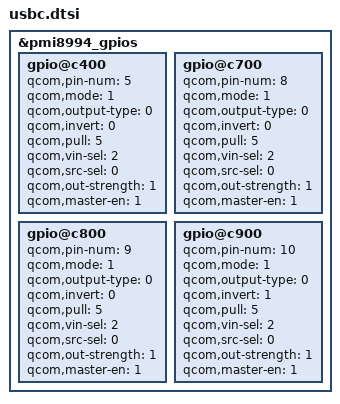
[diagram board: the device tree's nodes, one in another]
/*
 * Lumia 950 RM-1104 4VM_08r USB-C.
 *
 * Lattice iCE5LP2K (UC120 Type-C PHY, firmware bitstream) + TI HD3SS460
 * SuperSpeed mux. No USB Power Delivery. No HVDCP.
 *
 * HD3SS460 POL/AMSEL/EN sit next to GPIO_8/9/10 on sheet 4. Those cannot
 * be TLMM 8/9/10: MSM GPIO 10 is DISPLAY_TE. Hold the mux on PMI8994
 * GPIO 8/9/10 + GPIO 5 VBUS (already OTG switch). No PD PHY node.
 */

&pmi8994_gpios {
	gpio@c400 {	/* GPIO 5  USB_VBUS / OTG SWITCH */
		status = "okay";
		qcom,pin-num = <5>;
		qcom,mode = <1>;		/* digital output */
		qcom,output-type = <0>;		/* CMOS */
		qcom,invert = <0>;		/* VBUS off */
		qcom,pull = <5>;		/* no pull */
		qcom,vin-sel = <2>;		/* 1.8 V */
		qcom,src-sel = <0>;		/* constant */
		qcom,out-strength = <1>;	/* low */
		qcom,master-en = <1>;
	};

	gpio@c700 {	/* GPIO 8  HD3SS460 POL */
		status = "okay";
		qcom,pin-num = <8>;
		qcom,mode = <1>;
		qcom,output-type = <0>;
		qcom,invert = <0>;		/* POL 0 */
		qcom,pull = <5>;
		qcom,vin-sel = <2>;
		qcom,src-sel = <0>;
		qcom,out-strength = <1>;
		qcom,master-en = <1>;
	};

	gpio@c800 {	/* GPIO 9  HD3SS460 AMSEL */
		status = "okay";
		qcom,pin-num = <9>;
		qcom,mode = <1>;
		qcom,output-type = <0>;
		qcom,invert = <0>;		/* AMSEL 0 = USB, not DP */
		qcom,pull = <5>;
		qcom,vin-sel = <2>;
		qcom,src-sel = <0>;
		qcom,out-strength = <1>;
		qcom,master-en = <1>;
	};

	gpio@c900 {	/* GPIO 10 HD3SS460 EN */
		status = "okay";
		qcom,pin-num = <10>;
		qcom,mode = <1>;
		qcom,output-type = <0>;
		qcom,invert = <1>;		/* EN 1 */
		qcom,pull = <5>;
		qcom,vin-sel = <2>;
		qcom,src-sel = <0>;
		qcom,out-strength = <1>;
		qcom,master-en = <1>;
	};
};
